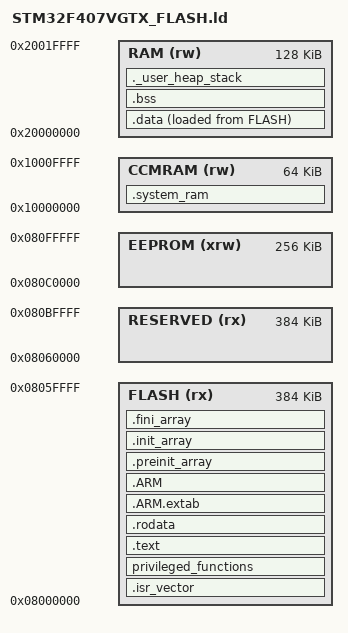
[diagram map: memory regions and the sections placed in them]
/**
 ******************************************************************************
 * @file      LinkerScript.ld
 * @author    Auto-generated by STM32CubeIDE
 * @brief     Linker script for STM32F407VGTx Device from STM32F4 series
 *                      1024Kbytes FLASH
 *                      64Kbytes CCMRAM
 *                      128Kbytes RAM
 *
 *            Set heap size, stack size and stack location according
 *            to application requirements.
 *
 *            Set memory bank area and size if external memory is used
 ******************************************************************************
 * @attention
 *
 * <h2><center>&copy; Copyright (c) 2020 STMicroelectronics.
 * All rights reserved.</center></h2>
 *
 * This software component is licensed by ST under BSD 3-Clause license,
 * the "License"; You may not use this file except in compliance with the
 * License. You may obtain a copy of the License at:
 *                        opensource.org/licenses/BSD-3-Clause
 *
 ******************************************************************************
 */

/* Entry Point */
ENTRY(Reset_Handler)

/* Highest address of the user mode stack */
_estack = ORIGIN(RAM) + LENGTH(RAM);	/* end of "RAM" Ram type memory */

_Min_Heap_Size = 0x200 ;	/* required amount of heap  */
/* MSP stack (Reset_Handler up to vTaskStartScheduler()). Doubled from
   0x400 to 0x800 after a HardFault showed it nearly exhausted. */
Stack_Size = 0x800 ;	/* required amount of stack */

/* Memories definition */
MEMORY
{
  CCMRAM    (rw)     : ORIGIN = 0x10000000,   LENGTH = 64K
  RAM    	(rw)	 : ORIGIN = 0x20000000,   LENGTH = 128K
  FLASH     (rx)     : ORIGIN = 0x8000000,    LENGTH = 384K
  RESERVED  (rx)     : ORIGIN = 0x8060000,    LENGTH = 384K  /*This block is for the firmware update process*/
  EEPROM (xrw)       : ORIGIN = 0x080C0000,   LENGTH = 256K
}

__FLASH_segment_start__ = ORIGIN( FLASH );
__FLASH_segment_end__ = __FLASH_segment_start__ + LENGTH( FLASH );

__SRAM_segment_start__ = ORIGIN( RAM );
__SRAM_segment_end__ = __SRAM_segment_start__ + LENGTH( RAM );

_Privileged_Functions_Region_Size = 0x4000;
_Privileged_Data_Region_Size = 256;
/* Must be a power of two - also the size of the COMMON_BLOCK MPU region
   (Core/Inc/common.h). Raised from 0x8000 to 0x10000: common_data content
   grew past the old 32 KB region with the WLAN-link feature. */
PROVIDE( _Common_Data_Region_Size = 0x10000);

/* Sections */
SECTIONS
{
  /* The startup code into "FLASH" Rom type memory */
  .isr_vector :
  {
    . = ALIGN(4);
    KEEP(*(.isr_vector)) /* Startup code */
    . = ALIGN(4);
  } >FLASH

	privileged_functions :
	{
 	__privileged_functions_start__ = . ;
	__syscalls_flash_start__ = . ;
		KEEP(*(.isr_vector))
		*(privileged_functions)
	. = ALIGN( _Privileged_Functions_Region_Size );
	__privileged_functions_end__ = .;
	__syscalls_flash_end__ = . ;
	} > FLASH	


  /* The program code and other data into "FLASH" Rom type memory */
  .text :
  {
    . = ALIGN(4);
    _stext = .;        /* define a global symbols at start of code */
    *(.text)           /* .text sections (code) */
    *(.text*)          /* .text* sections (code) */
    *(.glue_7)         /* glue arm to thumb code */
    *(.glue_7t)        /* glue thumb to arm code */
    *(.eh_frame)

    KEEP (*(.init))
    KEEP (*(.fini))

    . = ALIGN(4);
    _etext = .;        /* define a global symbols at end of code */
  } >FLASH

  /* Constant data into "FLASH" Rom type memory */
  .rodata :
  {
    . = ALIGN(4);
    *(.rodata)         /* .rodata sections (constants, strings, etc.) */
    *(.rodata*)        /* .rodata* sections (constants, strings, etc.) */
    . = ALIGN(4);
  } >FLASH

  .ARM.extab   : { 
    . = ALIGN(4);
    *(.ARM.extab* .gnu.linkonce.armextab.*)
    . = ALIGN(4);
  } >FLASH
  
  .ARM : {
    . = ALIGN(4);
    __exidx_start = .;
    *(.ARM.exidx*)
    __exidx_end = .;
    . = ALIGN(4);
  } >FLASH

  .preinit_array     :
  {
    . = ALIGN(4);
    PROVIDE_HIDDEN (__preinit_array_start = .);
    KEEP (*(.preinit_array*))
    PROVIDE_HIDDEN (__preinit_array_end = .);
    . = ALIGN(4);
  } >FLASH
  
  .init_array :
  {
    . = ALIGN(4);
    PROVIDE_HIDDEN (__init_array_start = .);
    KEEP (*(SORT(.init_array.*)))
    KEEP (*(.init_array*))
    PROVIDE_HIDDEN (__init_array_end = .);
    . = ALIGN(4);
  } >FLASH
  
  .fini_array :
  {
    . = ALIGN(4);
    PROVIDE_HIDDEN (__fini_array_start = .);
    KEEP (*(SORT(.fini_array.*)))
    KEEP (*(.fini_array*))
    PROVIDE_HIDDEN (__fini_array_end = .);
    . = ALIGN(4);
  } >FLASH

  /* Used by the startup to initialize data */
  _sidata = LOADADDR(.data);

  /* Initialized data sections into "RAM" Ram type memory */
  .data :
  {
    . = ALIGN(4);
    _sdata = .;        /* create a global symbol at data start */

	/* COMMON Block - placed first so its required alignment costs zero
	   padding (was after *(.data)/*(.data*), wasting padding there). */
	. = ALIGN( _Common_Data_Region_Size );
	__common_data_start__ = . ;
    *(common_data)
	. = ALIGN( _Common_Data_Region_Size );
	__common_data_end__ = . ;

	/* .mag_calc_data needs the same MPU power-of-two alignment - placed
	   here, right after __common_data_end__, so it's zero-cost too. */
	. = ALIGN(8192);
	__mag_calc_data_start__ = . ;
	KEEP(*(.mag_calc_data))
	KEEP(*(.mag_calc_data*))
	__mag_calc_data_end__ = . ;

    *(.data)           /* .data sections */
    *(.data*)          /* .data* sections */

    . = ALIGN(4);
    _edata = .;        /* define a global symbol at data end */

  } >RAM AT> FLASH

  /* Uninitialized data section into "RAM" Ram type memory */
  . = ALIGN(4);
  .bss :
  {
    /* This is used by the startup in order to initialize the .bss section */
    _sbss = .;         /* define a global symbol at bss start */
    __bss_start__ = _sbss;
    *(.bss)
    *(.bss*)
    *(COMMON)

    . = ALIGN(4);
    _ebss = .;         /* define a global symbol at bss end */
    __bss_end__ = _ebss;
  } >RAM

  /* User_heap_stack section, used to check that there is enough "RAM" Ram  type memory left */
  ._user_heap_stack :
  {
    . = ALIGN(8);
    PROVIDE ( end = . );
    PROVIDE ( _end = . );
    . = . + _Min_Heap_Size;
    . = ALIGN(8);
  } >RAM

  /* Core Coupled Memory CCM section */
  .system_ram(NOLOAD) :
  {
  	. = . + Stack_Size;
  	_estack = .;
    /* This is used by the startup in order to initialize the .bss secion */
    _s_system_ram = .;         /* define a global symbol at bss start */

	/* FreeRTOS System Memory */
	. = ALIGN( _Privileged_Data_Region_Size );
	__privileged_data_start__ = . ;
    *(privileged_data)
	. = ALIGN( _Privileged_Data_Region_Size );
	__privileged_data_end__ = . ;

	/* user data block, mainly used for task stacks */
	__user_data_start__ = . ;
    *(user_data)
	__user_data_end__ = . ;

	/* Statically pre-aligned RestrictedTask stack buffers, reserved here
	   instead of via pvPortMallocAlignedMemory() (which HardFaulted once
	   the heap stopped reliably having a matching-aligned free block).
	   Lives in CCMRAM (RAM has no headroom for it); CCM is unreachable by
	   DMA, so no contributing stack may be a DMA source/destination. Each
	   contributing object must still declare its own
	   __attribute__((aligned(N))) matching its size. */
	. = ALIGN(8192);
	__wlan_task_stacks_start__ = . ;
	*(wlan_task_stacks)
	__wlan_task_stacks_end__ = . ;

	/* One-shot "flash update already attempted this power-cycle" marker
	   (uSD_handler.cpp/uSD_helpers.cpp) - deliberately kept out of .bss:
	   this whole (NOLOAD) section is never zero-filled by the startup
	   code's LoopFillZerobss, so the marker survives a warm reset (WWDG,
	   SCB::sys_reset()) intact, while a genuine power-on reset loses CCM
	   RAM content and leaves it reading as effectively random - see
	   documentation/wlan_link.md. */
	. = ALIGN(4);
	__firmware_update_retry_marker_start__ = . ;
	*(noinit_firmware_update_retry_marker)
	__firmware_update_retry_marker_end__ = . ;

	/* Boot-scoped diagnostic counters (reset_count, flash_erase_count -
	   uSD_handler.cpp) - same NoInit mechanism as the marker above, but
	   explicitly reset to 0 on a genuine power-on/brown-out reset (checked
	   via RCC's PORRSTF/BORRSTF flags) rather than just relying on CCM RAM
	   happening to read as something on power-up; a warm reset leaves them
	   counting across the reset instead. */
	. = ALIGN(4);
	__boot_counters_start__ = . ;
	*(noinit_boot_counters)
	__boot_counters_end__ = . ;

	/* FreeRTOS heap block, used for task stacks, queues, semaphores etc. */
    . = ALIGN(4);
	__FreeRTOS_heap_begin__ = . ;
/*    . = . + _FreeRTOS_heap_size; unused, use all remaining space ! */ 

    . = ALIGN(0x10000); /* locate this to end of CCM */
/*	equiv.: . = __CCRAM_segment_end__;	*/

	__FreeRTOS_heap_end__ = .;
    _e_system_ram = .;
  } >CCMRAM

  /* Remove information from the compiler libraries */
  /DISCARD/ :
  {
    libc.a ( * )
    libm.a ( * )
    libgcc.a ( * )
  }

  .ARM.attributes 0 : { *(.ARM.attributes) }
}
